VERSION "0.1.0"

NS_ :

BS_:

BU_: RT_CORE SAFETY IO CONN LINUX HIL_SIM TESTER

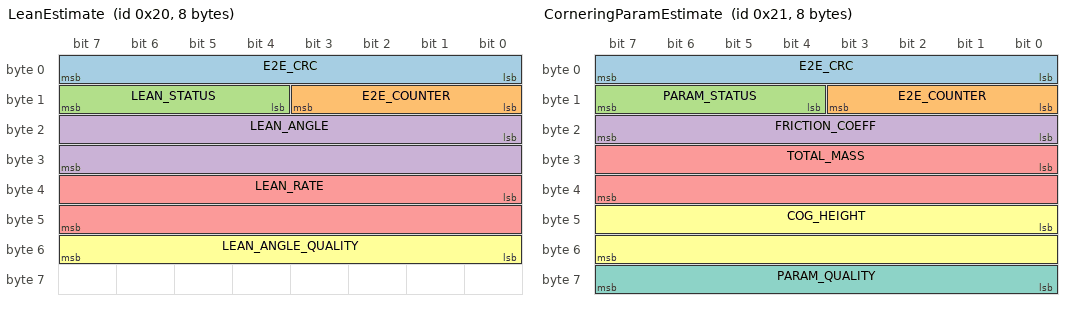
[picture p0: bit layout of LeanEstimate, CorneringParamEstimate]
BO_ 32 LeanEstimate: 8 RT_CORE
 SG_ E2E_CRC : 0|8@1+ (1,0) [0|255] "" SAFETY,LINUX
 SG_ E2E_COUNTER : 8|4@1+ (1,0) [0|15] "" SAFETY,LINUX
 SG_ LEAN_STATUS : 12|4@1+ (1,0) [0|15] "" SAFETY,LINUX
 SG_ LEAN_ANGLE : 16|16@1- (0.01,0) [-90|90] "deg" SAFETY,LINUX
 SG_ LEAN_RATE : 32|16@1- (0.01,0) [-300|300] "deg/s" SAFETY,LINUX
 SG_ LEAN_ANGLE_QUALITY : 48|8@1+ (1,0) [0|100] "%" SAFETY,LINUX

BO_ 33 CorneringParamEstimate: 8 RT_CORE
 SG_ E2E_CRC : 0|8@1+ (1,0) [0|255] "" SAFETY,LINUX
 SG_ E2E_COUNTER : 8|4@1+ (1,0) [0|15] "" SAFETY,LINUX
 SG_ PARAM_STATUS : 12|4@1+ (1,0) [0|15] "" SAFETY,LINUX
 SG_ FRICTION_COEFF : 16|8@1+ (0.01,0) [0|1.5] "" SAFETY,LINUX
 SG_ TOTAL_MASS : 24|16@1+ (0.1,0) [0|1000] "kg" SAFETY,LINUX
 SG_ COG_HEIGHT : 40|16@1+ (0.001,0) [0|2] "m" SAFETY,LINUX
 SG_ PARAM_QUALITY : 56|8@1+ (1,0) [0|100] "%" SAFETY,LINUX

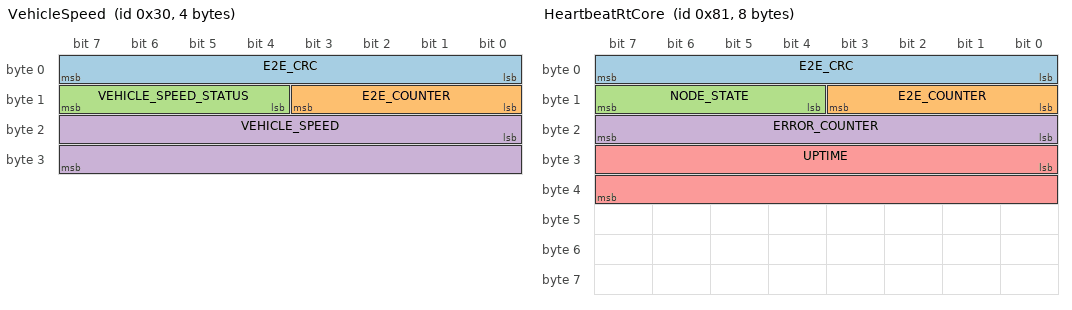
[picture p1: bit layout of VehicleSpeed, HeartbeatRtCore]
BO_ 48 VehicleSpeed: 4 RT_CORE
 SG_ E2E_CRC : 0|8@1+ (1,0) [0|255] "" SAFETY,IO,CONN,LINUX
 SG_ E2E_COUNTER : 8|4@1+ (1,0) [0|15] "" SAFETY,IO,CONN,LINUX
 SG_ VEHICLE_SPEED_STATUS : 12|4@1+ (1,0) [0|15] "" SAFETY,IO,CONN,LINUX
 SG_ VEHICLE_SPEED : 16|16@1+ (0.01,0) [0|300] "km/h" SAFETY,IO,CONN,LINUX

BO_ 129 HeartbeatRtCore: 8 RT_CORE
 SG_ E2E_CRC : 0|8@1+ (1,0) [0|255] "" SAFETY,LINUX
 SG_ E2E_COUNTER : 8|4@1+ (1,0) [0|15] "" SAFETY,LINUX
 SG_ NODE_STATE : 12|4@1+ (1,0) [0|15] "" SAFETY,LINUX
 SG_ ERROR_COUNTER : 16|8@1+ (1,0) [0|255] "" SAFETY,LINUX
 SG_ UPTIME : 24|16@1+ (1,0) [0|65535] "s" SAFETY,LINUX

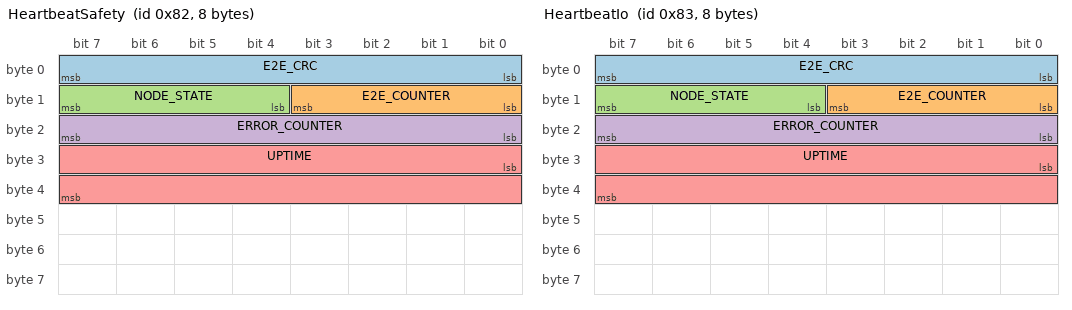
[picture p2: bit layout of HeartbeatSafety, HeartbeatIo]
BO_ 130 HeartbeatSafety: 8 SAFETY
 SG_ E2E_CRC : 0|8@1+ (1,0) [0|255] "" RT_CORE,LINUX
 SG_ E2E_COUNTER : 8|4@1+ (1,0) [0|15] "" RT_CORE,LINUX
 SG_ NODE_STATE : 12|4@1+ (1,0) [0|15] "" RT_CORE,LINUX
 SG_ ERROR_COUNTER : 16|8@1+ (1,0) [0|255] "" RT_CORE,LINUX
 SG_ UPTIME : 24|16@1+ (1,0) [0|65535] "s" RT_CORE,LINUX

BO_ 131 HeartbeatIo: 8 IO
 SG_ E2E_CRC : 0|8@1+ (1,0) [0|255] "" RT_CORE,LINUX
 SG_ E2E_COUNTER : 8|4@1+ (1,0) [0|15] "" RT_CORE,LINUX
 SG_ NODE_STATE : 12|4@1+ (1,0) [0|15] "" RT_CORE,LINUX
 SG_ ERROR_COUNTER : 16|8@1+ (1,0) [0|255] "" RT_CORE,LINUX
 SG_ UPTIME : 24|16@1+ (1,0) [0|65535] "s" RT_CORE,LINUX

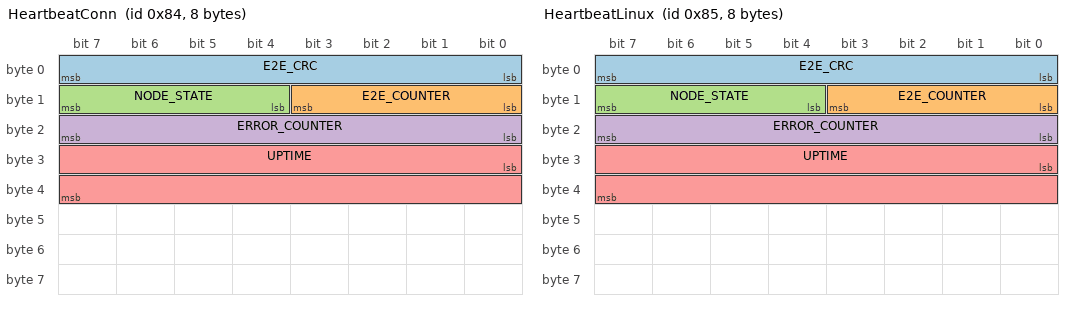
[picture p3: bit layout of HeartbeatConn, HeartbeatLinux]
BO_ 132 HeartbeatConn: 8 CONN
 SG_ E2E_CRC : 0|8@1+ (1,0) [0|255] "" RT_CORE,LINUX
 SG_ E2E_COUNTER : 8|4@1+ (1,0) [0|15] "" RT_CORE,LINUX
 SG_ NODE_STATE : 12|4@1+ (1,0) [0|15] "" RT_CORE,LINUX
 SG_ ERROR_COUNTER : 16|8@1+ (1,0) [0|255] "" RT_CORE,LINUX
 SG_ UPTIME : 24|16@1+ (1,0) [0|65535] "s" RT_CORE,LINUX

BO_ 133 HeartbeatLinux: 8 LINUX
 SG_ E2E_CRC : 0|8@1+ (1,0) [0|255] "" RT_CORE
 SG_ E2E_COUNTER : 8|4@1+ (1,0) [0|15] "" RT_CORE
 SG_ NODE_STATE : 12|4@1+ (1,0) [0|15] "" RT_CORE
 SG_ ERROR_COUNTER : 16|8@1+ (1,0) [0|255] "" RT_CORE
 SG_ UPTIME : 24|16@1+ (1,0) [0|65535] "s" RT_CORE

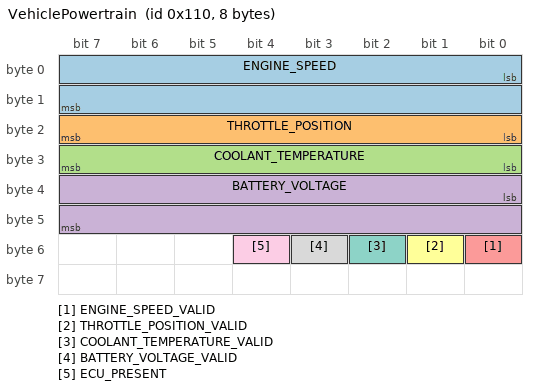
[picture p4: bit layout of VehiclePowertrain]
BO_ 272 VehiclePowertrain: 8 RT_CORE
 SG_ ENGINE_SPEED : 0|16@1+ (0.25,0) [0|16383.75] "rpm" CONN,LINUX
 SG_ THROTTLE_POSITION : 16|8@1+ (0.4,0) [0|100] "%" CONN,LINUX
 SG_ COOLANT_TEMPERATURE : 24|8@1+ (1,-40) [-40|215] "degC" CONN,LINUX
 SG_ BATTERY_VOLTAGE : 32|16@1+ (0.001,0) [0|65.535] "V" CONN,LINUX
 SG_ ENGINE_SPEED_VALID : 48|1@1+ (1,0) [0|1] "" CONN,LINUX
 SG_ THROTTLE_POSITION_VALID : 49|1@1+ (1,0) [0|1] "" CONN,LINUX
 SG_ COOLANT_TEMPERATURE_VALID : 50|1@1+ (1,0) [0|1] "" CONN,LINUX
 SG_ BATTERY_VOLTAGE_VALID : 51|1@1+ (1,0) [0|1] "" CONN,LINUX
 SG_ ECU_PRESENT : 52|1@1+ (1,0) [0|1] "" CONN,LINUX

CM_ "moto-platform platform CAN bus (classic CAN 500 kbps, 11-bit IDs). ID plan and E2E rules: docs/ARCHITECTURE.md section 4. Single source of truth; consumers use gen/ output only.";
CM_ BU_ RT_CORE "Node ID 1. STM32H7 domain controller. Sole vehicle-bus tester (D-021); republishes decoded vehicle signals here.";
CM_ BU_ SAFETY "Node ID 2. STM32G4 cornering safety decision (isolated).";
CM_ BU_ IO "Node ID 3. STM32G0 blind spot, immobilizer, power management.";
CM_ BU_ CONN "Node ID 4. ESP32-S3 Wi-Fi/BLE/voice.";
CM_ BU_ LINUX "Node ID 5. Raspberry Pi 5 (Kuksa via kuksa-can-provider).";
CM_ BU_ HIL_SIM "Node ID 0xE. HIL restbus simulator.";
CM_ BU_ TESTER "Node ID 0xF. External diagnostic tester.";
CM_ BO_ 32 "rt-core EKF (Layer 2) lean estimate for the cornering decision. Safety range, E2E protected.";
CM_ SG_ 32 LEAN_ANGLE "Roll angle, ISO 8855: positive = right side down.";
CM_ SG_ 32 LEAN_RATE "Roll rate, ISO 8855: positive = rolling to the right.";
CM_ SG_ 32 LEAN_ANGLE_QUALITY "EKF confidence in LEAN_ANGLE, 0 = none, 100 = full.";
CM_ SG_ 32 LEAN_STATUS "0 = NOT_AVAILABLE so an all-zero payload is never valid. Codes 5-15 are invalid. Whether CLAMPED/DEFAULT_FALLBACK may be used by the safety decision is open (Q-002).";
CM_ BO_ 33 "rt-core EKF (Layer 2) cornering parameters, clamped to physical ranges by rt-core. Safety range, E2E protected.";
CM_ SG_ 33 FRICTION_COEFF "Estimated tyre-road friction coefficient (mu). The DBC range is a transport range, not a safety ceiling: safety-node applies its own fixed ceiling.";
CM_ SG_ 33 TOTAL_MASS "Estimated vehicle + rider + load mass. Transport range only; physically implausible values (e.g. 0) mean INVALID at the consumer, never clamped (plausibility limits to be set with Q-002).";
CM_ SG_ 33 COG_HEIGHT "Estimated centre-of-gravity height above ground. Transport range only; implausible values (e.g. 0) mean INVALID at the consumer.";
CM_ SG_ 33 PARAM_QUALITY "EKF confidence in the parameters, 0 = none, 100 = full.";
CM_ SG_ 33 PARAM_STATUS "0 = NOT_AVAILABLE so an all-zero payload is never valid. Codes 5-15 are invalid. Use of CLAMPED/DEFAULT_FALLBACK values is open (Q-002).";
CM_ BO_ 48 "Vehicle speed republished by rt-core from the CL250 ECU (uds/vehicle_cl250.yaml DID 0xF40D, D-021). Consumed by safety-node, so safety range and E2E protected.";
CM_ SG_ 48 VEHICLE_SPEED_STATUS "0 = NOT_AVAILABLE so an all-zero payload is never valid. VALID only while the polled source value is younger than twice its poll period (uds/vehicle_cl250.yaml; 1600 ms at the current 800 ms), else STALE. rt-core keeps sending at the cycle time. E2E proves frame freshness, not value freshness; whether that source age is acceptable for the safety decision is open (Q-002).";
CM_ BO_ 129 "Heartbeat of RT_CORE (0x080 + node ID 1). Monitored by safety-node.";
CM_ BO_ 130 "Heartbeat of SAFETY (0x080 + node ID 2).";
CM_ BO_ 131 "Heartbeat of IO (0x080 + node ID 3).";
CM_ BO_ 132 "Heartbeat of CONN (0x080 + node ID 4).";
CM_ BO_ 133 "Heartbeat of LINUX (0x080 + node ID 5).";
CM_ BO_ 272 "CL250 powertrain values republished by rt-core from polled ECU DIDs (uds/vehicle_cl250.yaml, D-021). Each *_VALID bit is 1 only while that value is fresh.";
CM_ SG_ 272 ECU_PRESENT "1 while the engine ECU answered any request within ecu_absent_timeout_ms.";
BA_DEF_ BO_ "GenMsgCycleTime" INT 0 10000;
BA_DEF_ BO_ "E2E_Protected" ENUM "No","Yes";
BA_DEF_ BO_ "E2E_DataID" INT 0 65535;
BA_DEF_ BU_ "NodeId" INT 0 15;
BA_DEF_DEF_ "GenMsgCycleTime" 0;
BA_DEF_DEF_ "E2E_Protected" "No";
BA_DEF_DEF_ "E2E_DataID" 0;
BA_DEF_DEF_ "NodeId" 0;
BA_ "NodeId" BU_ RT_CORE 1;
BA_ "NodeId" BU_ SAFETY 2;
BA_ "NodeId" BU_ IO 3;
BA_ "NodeId" BU_ CONN 4;
BA_ "NodeId" BU_ LINUX 5;
BA_ "NodeId" BU_ HIL_SIM 14;
BA_ "NodeId" BU_ TESTER 15;
BA_ "GenMsgCycleTime" BO_ 32 20;
BA_ "E2E_Protected" BO_ 32 1;
BA_ "E2E_DataID" BO_ 32 32;
BA_ "GenMsgCycleTime" BO_ 33 100;
BA_ "E2E_Protected" BO_ 33 1;
BA_ "E2E_DataID" BO_ 33 33;
BA_ "GenMsgCycleTime" BO_ 48 100;
BA_ "E2E_Protected" BO_ 48 1;
BA_ "E2E_DataID" BO_ 48 48;
BA_ "GenMsgCycleTime" BO_ 129 100;
BA_ "E2E_Protected" BO_ 129 1;
BA_ "E2E_DataID" BO_ 129 129;
BA_ "GenMsgCycleTime" BO_ 130 100;
BA_ "E2E_Protected" BO_ 130 1;
BA_ "E2E_DataID" BO_ 130 130;
BA_ "GenMsgCycleTime" BO_ 131 100;
BA_ "E2E_Protected" BO_ 131 1;
BA_ "E2E_DataID" BO_ 131 131;
BA_ "GenMsgCycleTime" BO_ 132 100;
BA_ "E2E_Protected" BO_ 132 1;
BA_ "E2E_DataID" BO_ 132 132;
BA_ "GenMsgCycleTime" BO_ 133 100;
BA_ "E2E_Protected" BO_ 133 1;
BA_ "E2E_DataID" BO_ 133 133;
BA_ "GenMsgCycleTime" BO_ 272 50;
VAL_ 32 LEAN_STATUS 0 "NOT_AVAILABLE" 1 "VALID" 2 "CLAMPED" 3 "DEFAULT_FALLBACK" 4 "NOT_CONVERGED" ;
VAL_ 33 PARAM_STATUS 0 "NOT_AVAILABLE" 1 "VALID" 2 "CLAMPED" 3 "DEFAULT_FALLBACK" 4 "NOT_CONVERGED" ;
VAL_ 48 VEHICLE_SPEED_STATUS 0 "NOT_AVAILABLE" 1 "VALID" 2 "STALE" 3 "ECU_ABSENT" ;
VAL_ 129 NODE_STATE 0 "INIT" 1 "NORMAL" 2 "DEGRADED" 3 "FAULT" 4 "BOOTLOADER" ;
VAL_ 130 NODE_STATE 0 "INIT" 1 "NORMAL" 2 "DEGRADED" 3 "FAULT" 4 "BOOTLOADER" ;
VAL_ 131 NODE_STATE 0 "INIT" 1 "NORMAL" 2 "DEGRADED" 3 "FAULT" 4 "BOOTLOADER" ;
VAL_ 132 NODE_STATE 0 "INIT" 1 "NORMAL" 2 "DEGRADED" 3 "FAULT" 4 "BOOTLOADER" ;
VAL_ 133 NODE_STATE 0 "INIT" 1 "NORMAL" 2 "DEGRADED" 3 "FAULT" 4 "BOOTLOADER" ;
